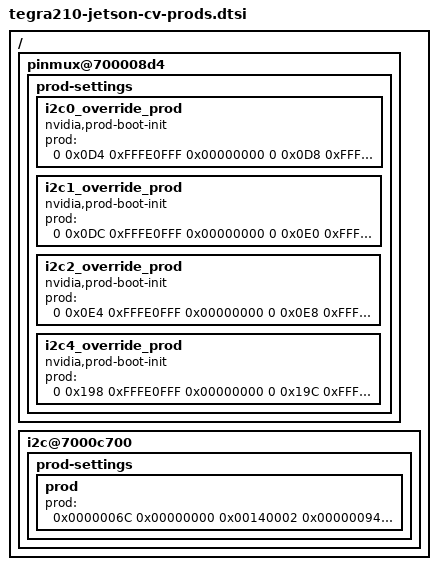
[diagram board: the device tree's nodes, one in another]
/*
 * Copyright (c) 2015, NVIDIA CORPORATION.  All rights reserved.
 *
 * This program is free software; you can redistribute it and/or modify
 * it under the terms of the GNU General Public License as published by
 * the Free Software Foundation; version 2 of the License.
 *
 * This program is distributed in the hope that it will be useful, but WITHOUT
 * ANY WARRANTY; without even the implied warranty of MERCHANTABILITY or
 * FITNESS FOR A PARTICULAR PURPOSE.  See the GNU General Public License for
 * more details.
 *
 * You should have received a copy of the GNU General Public License along
 * with this program; if not, write to the Free Software Foundation, Inc.,
 * 51 Franklin Street, Fifth Floor, Boston, MA  02110-1301, USA.
 *
 */

/ {
	pinmux@700008d4 {
		prod-settings {
			i2c0_override_prod {
				nvidia,prod-boot-init;
				prod = <
					0 0x0D4 0xFFFE0FFF 0x00000000
					0 0x0D8 0xFFFE0FFF 0x00000000
				>;
			};
			i2c1_override_prod {
				nvidia,prod-boot-init;
				prod = <
					0 0x0DC 0xFFFE0FFF 0x00000000
					0 0x0E0 0xFFFE0FFF 0x00000000
				>;
			};
			i2c2_override_prod {
				nvidia,prod-boot-init;
				prod = <
					0 0x0E4 0xFFFE0FFF 0x00000000
					0 0x0E8 0xFFFE0FFF 0x00000000
				>;
			};
			i2c4_override_prod {
				nvidia,prod-boot-init;
				prod = <
					0 0x198 0xFFFE0FFF 0x00000000
					0 0x19C 0xFFFE0FFF 0x00000000
					1 0x0DC 0xFFFFFEFF 0x00000100
					1 0x0E0 0xFFFFFEFF 0x00000100
				>;
			};
		};
	};

	i2c@7000c700 {
		prod-settings {
			#prod-cells = <3>;
			prod {
				prod = <
					0x0000006C 0x00000000 0x00140002
					0x00000094 0xFFFFC0FF 0x00000400
				>;
			};
		};
	};
};
